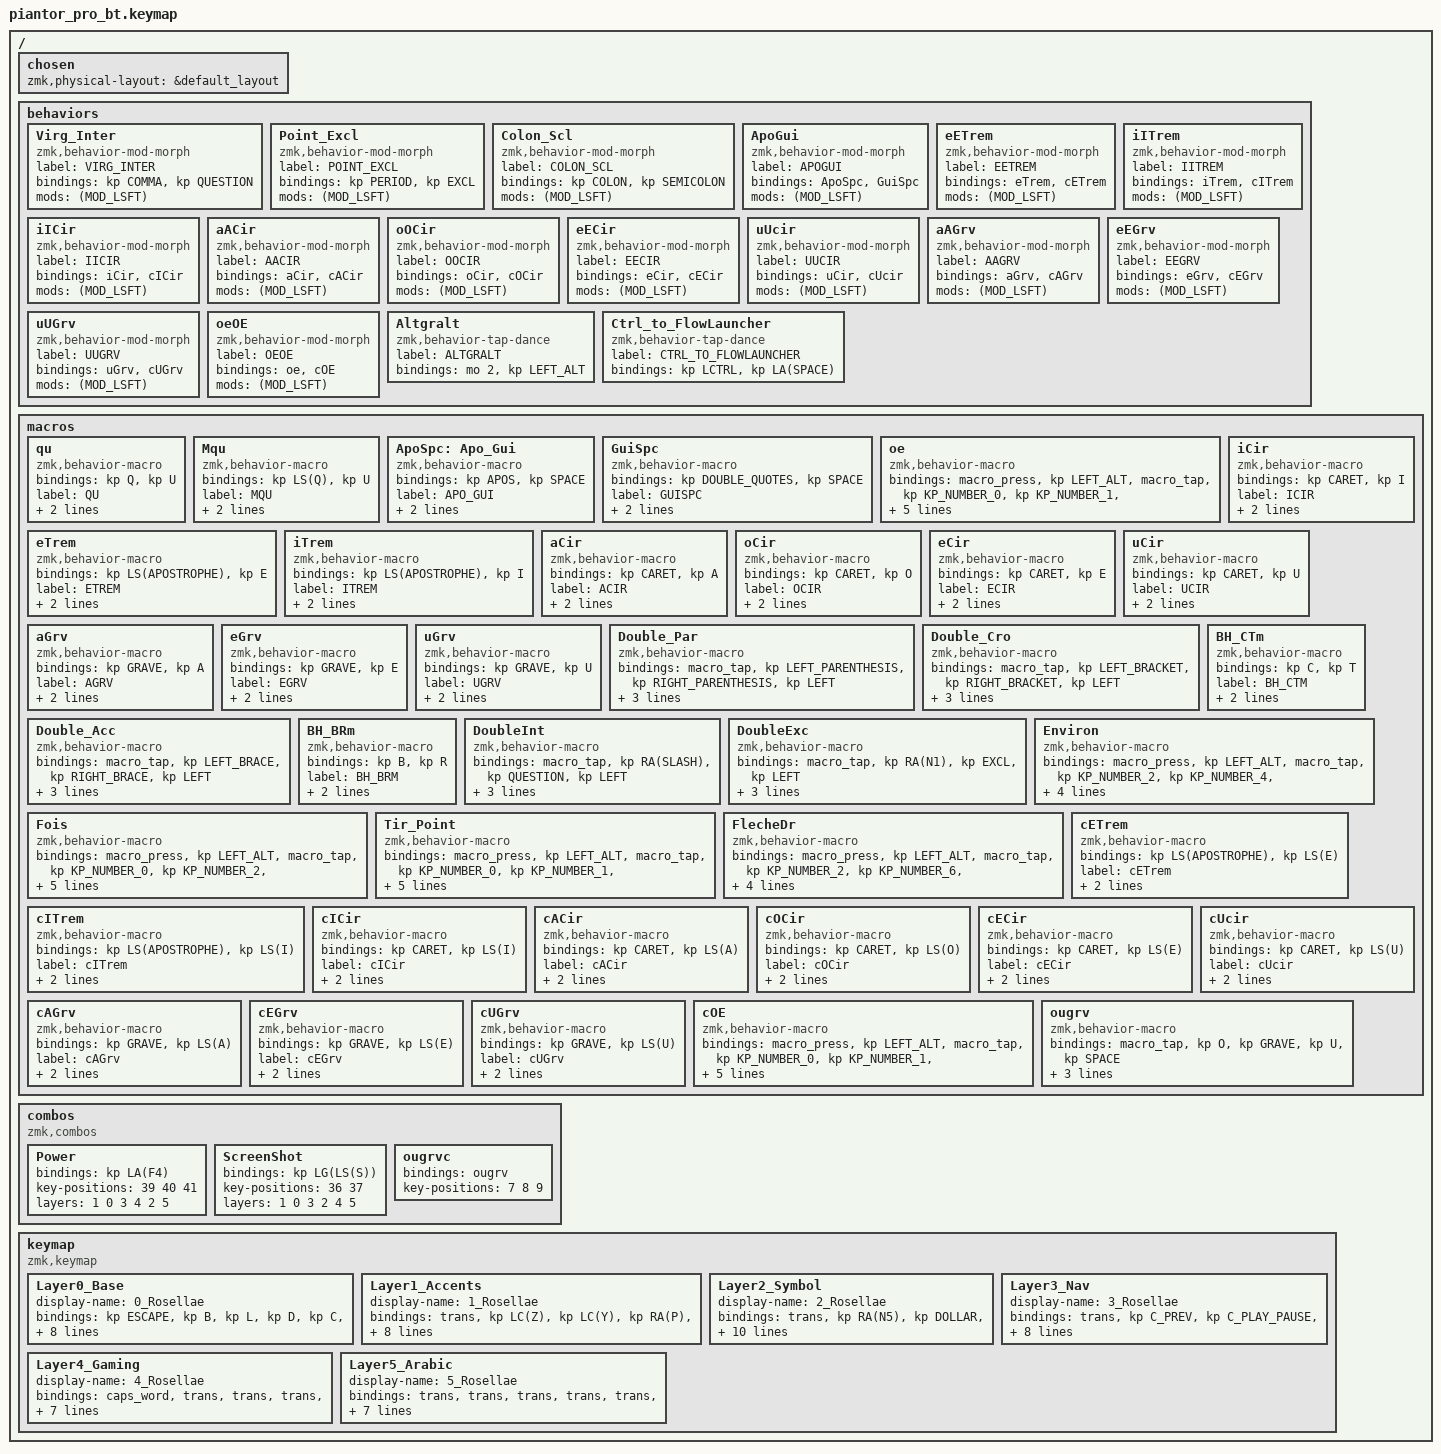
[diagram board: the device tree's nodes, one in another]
/*
 * Copyright (c) 2020 The ZMK Contributors
 *
 * SPDX-License-Identifier: MIT
 */

#include <behaviors.dtsi>
#include <dt-bindings/zmk/keys.h>

/ {
    chosen { zmk,physical-layout = &default_layout; };
};

/ {
    behaviors {
        Virg_Inter: Virg_Inter {
            compatible = "zmk,behavior-mod-morph";
            label = "VIRG_INTER";
            bindings = <&kp COMMA>, <&kp QUESTION>;

            #binding-cells = <0>;
            mods = <(MOD_LSFT)>;
        };

        Point_Excl: Point_Excl {
            compatible = "zmk,behavior-mod-morph";
            label = "POINT_EXCL";
            bindings = <&kp PERIOD>, <&kp EXCL>;

            #binding-cells = <0>;
            mods = <(MOD_LSFT)>;
        };

        Colon_Scl: Colon_Scl {
            compatible = "zmk,behavior-mod-morph";
            label = "COLON_SCL";
            bindings = <&kp COLON>, <&kp SEMICOLON>;

            #binding-cells = <0>;
            mods = <(MOD_LSFT)>;
        };

        ApoGui: ApoGui {
            compatible = "zmk,behavior-mod-morph";
            label = "APOGUI";
            bindings = <&ApoSpc>, <&GuiSpc>;

            #binding-cells = <0>;
            mods = <(MOD_LSFT)>;
        };

        eETrem: eETrem {
            compatible = "zmk,behavior-mod-morph";
            label = "EETREM";
            bindings = <&eTrem>, <&cETrem>;

            #binding-cells = <0>;
            mods = <(MOD_LSFT)>;
        };

        iITrem: iITrem {
            compatible = "zmk,behavior-mod-morph";
            label = "IITREM";
            bindings = <&iTrem>, <&cITrem>;

            #binding-cells = <0>;
            mods = <(MOD_LSFT)>;
        };

        iICir: iICir {
            compatible = "zmk,behavior-mod-morph";
            label = "IICIR";
            bindings = <&iCir>, <&cICir>;

            #binding-cells = <0>;
            mods = <(MOD_LSFT)>;
        };

        aACir: aACir {
            compatible = "zmk,behavior-mod-morph";
            label = "AACIR";
            bindings = <&aCir>, <&cACir>;

            #binding-cells = <0>;
            mods = <(MOD_LSFT)>;
        };

        oOCir: oOCir {
            compatible = "zmk,behavior-mod-morph";
            label = "OOCIR";
            bindings = <&oCir>, <&cOCir>;

            #binding-cells = <0>;
            mods = <(MOD_LSFT)>;
        };

        eECir: eECir {
            compatible = "zmk,behavior-mod-morph";
            label = "EECIR";
            bindings = <&eCir>, <&cECir>;

            #binding-cells = <0>;
            mods = <(MOD_LSFT)>;
        };

        uUcir: uUcir {
            compatible = "zmk,behavior-mod-morph";
            label = "UUCIR";
            bindings = <&uCir>, <&cUcir>;

            #binding-cells = <0>;
            mods = <(MOD_LSFT)>;
        };

        aAGrv: aAGrv {
            compatible = "zmk,behavior-mod-morph";
            label = "AAGRV";
            bindings = <&aGrv>, <&cAGrv>;

            #binding-cells = <0>;
            mods = <(MOD_LSFT)>;
        };

        eEGrv: eEGrv {
            compatible = "zmk,behavior-mod-morph";
            label = "EEGRV";
            bindings = <&eGrv>, <&cEGrv>;

            #binding-cells = <0>;
            mods = <(MOD_LSFT)>;
        };

        uUGrv: uUGrv {
            compatible = "zmk,behavior-mod-morph";
            label = "UUGRV";
            bindings = <&uGrv>, <&cUGrv>;

            #binding-cells = <0>;
            mods = <(MOD_LSFT)>;
        };

        oeOE: oeOE {
            compatible = "zmk,behavior-mod-morph";
            label = "OEOE";
            bindings = <&oe>, <&cOE>;

            #binding-cells = <0>;
            mods = <(MOD_LSFT)>;
        };

        Altgralt: Altgralt {
            compatible = "zmk,behavior-tap-dance";
            label = "ALTGRALT";
            #binding-cells = <0>;
            bindings = <&mo 2>, <&kp LEFT_ALT>;
        };

        Ctrl_to_FlowLauncher: Ctrl_to_FlowLauncher {
            compatible = "zmk,behavior-tap-dance";
            label = "CTRL_TO_FLOWLAUNCHER";
            #binding-cells = <0>;
            bindings = <&kp LCTRL>, <&kp LA(SPACE)>;
        };
    };

    macros {
        qu: qu {
            compatible = "zmk,behavior-macro";
            #binding-cells = <0>;
            bindings = <&kp Q &kp U>;
            label = "QU";
            wait-ms = <0>;
            tap-ms = <5>;
        };

        Mqu: Mqu {
            compatible = "zmk,behavior-macro";
            #binding-cells = <0>;
            bindings = <&kp LS(Q) &kp U>;
            label = "MQU";
            wait-ms = <0>;
            tap-ms = <5>;
        };

        ApoSpc: Apo_Gui {
            compatible = "zmk,behavior-macro";
            #binding-cells = <0>;
            bindings = <&kp APOS &kp SPACE>;
            label = "APO_GUI";
            wait-ms = <0>;
            tap-ms = <5>;
        };

        GuiSpc: GuiSpc {
            compatible = "zmk,behavior-macro";
            #binding-cells = <0>;
            bindings = <&kp DOUBLE_QUOTES &kp SPACE>;
            label = "GUISPC";
            wait-ms = <0>;
            tap-ms = <5>;
        };

        oe: oe {
            compatible = "zmk,behavior-macro";
            #binding-cells = <0>;
            bindings =
                <&macro_press>,
                <&kp LEFT_ALT>,
                <&macro_tap>,
                <&kp KP_NUMBER_0 &kp KP_NUMBER_1 &kp KP_NUMBER_5 &kp KP_NUMBER_6>,
                <&macro_release>,
                <&kp LEFT_ALT>;

            label = "OE";
            wait-ms = <10>;
            tap-ms = <10>;
        };

        eTrem: eTrem {
            compatible = "zmk,behavior-macro";
            #binding-cells = <0>;
            bindings = <&kp LS(APOSTROPHE) &kp E>;
            label = "ETREM";
            wait-ms = <0>;
            tap-ms = <5>;
        };

        iTrem: iTrem {
            compatible = "zmk,behavior-macro";
            #binding-cells = <0>;
            bindings = <&kp LS(APOSTROPHE) &kp I>;
            label = "ITREM";
            wait-ms = <0>;
            tap-ms = <5>;
        };

        iCir: iCir {
            compatible = "zmk,behavior-macro";
            #binding-cells = <0>;
            bindings = <&kp CARET &kp I>;
            label = "ICIR";
            wait-ms = <0>;
            tap-ms = <5>;
        };

        aCir: aCir {
            compatible = "zmk,behavior-macro";
            #binding-cells = <0>;
            bindings = <&kp CARET &kp A>;
            label = "ACIR";
            wait-ms = <0>;
            tap-ms = <5>;
        };

        oCir: oCir {
            compatible = "zmk,behavior-macro";
            #binding-cells = <0>;
            bindings = <&kp CARET &kp O>;
            label = "OCIR";
            wait-ms = <0>;
            tap-ms = <5>;
        };

        eCir: eCir {
            compatible = "zmk,behavior-macro";
            #binding-cells = <0>;
            bindings = <&kp CARET &kp E>;
            label = "ECIR";
            wait-ms = <0>;
            tap-ms = <5>;
        };

        uCir: uCir {
            compatible = "zmk,behavior-macro";
            #binding-cells = <0>;
            bindings = <&kp CARET &kp U>;
            label = "UCIR";
            wait-ms = <0>;
            tap-ms = <5>;
        };

        aGrv: aGrv {
            compatible = "zmk,behavior-macro";
            #binding-cells = <0>;
            bindings = <&kp GRAVE &kp A>;
            label = "AGRV";
            wait-ms = <0>;
            tap-ms = <5>;
        };

        eGrv: eGrv {
            compatible = "zmk,behavior-macro";
            #binding-cells = <0>;
            bindings = <&kp GRAVE &kp E>;
            label = "EGRV";
            wait-ms = <0>;
            tap-ms = <5>;
        };

        uGrv: uGrv {
            compatible = "zmk,behavior-macro";
            #binding-cells = <0>;
            bindings = <&kp GRAVE &kp U>;
            label = "UGRV";
            wait-ms = <0>;
            tap-ms = <5>;
        };

        Double_Par: Double_Par {
            compatible = "zmk,behavior-macro";
            #binding-cells = <0>;
            bindings =
                <&macro_tap>,
                <&kp LEFT_PARENTHESIS &kp RIGHT_PARENTHESIS &kp LEFT>;

            label = "Double_Par";
            wait-ms = <0>;
            tap-ms = <5>;
        };

        Double_Cro: Double_Cro {
            compatible = "zmk,behavior-macro";
            #binding-cells = <0>;
            bindings =
                <&macro_tap>,
                <&kp LEFT_BRACKET &kp RIGHT_BRACKET &kp LEFT>;

            label = "Double_Cro";
            wait-ms = <0>;
            tap-ms = <5>;
        };

        Double_Acc: Double_Acc {
            compatible = "zmk,behavior-macro";
            #binding-cells = <0>;
            bindings = <&macro_tap>, <&kp LEFT_BRACE &kp RIGHT_BRACE &kp LEFT>;

            label = "Double_Acc";
            wait-ms = <0>;
            tap-ms = <5>;
        };

        BH_CTm: BH_CTm {
            compatible = "zmk,behavior-macro";
            #binding-cells = <0>;
            bindings = <&kp C &kp T>;
            label = "BH_CTM";
            wait-ms = <0>;
            tap-ms = <5>;
        };

        BH_BRm: BH_BRm {
            compatible = "zmk,behavior-macro";
            #binding-cells = <0>;
            bindings = <&kp B &kp R>;
            label = "BH_BRM";
            wait-ms = <0>;
            tap-ms = <5>;
        };

        DoubleInt: DoubleInt {
            compatible = "zmk,behavior-macro";
            #binding-cells = <0>;
            bindings = <&macro_tap>, <&kp RA(SLASH) &kp QUESTION &kp LEFT>;

            label = "DOUBLEINT";
            wait-ms = <0>;
            tap-ms = <5>;
        };

        DoubleExc: DoubleExc {
            compatible = "zmk,behavior-macro";
            #binding-cells = <0>;
            bindings = <&macro_tap>, <&kp RA(N1) &kp EXCL &kp LEFT>;

            label = "DOUBLEEXC";
            wait-ms = <0>;
            tap-ms = <5>;
        };

        Environ: Environ {
            compatible = "zmk,behavior-macro";
            #binding-cells = <0>;
            bindings =
                <&macro_press>,
                <&kp LEFT_ALT>,
                <&macro_tap>,
                <&kp KP_NUMBER_2 &kp KP_NUMBER_4 &kp KP_NUMBER_7>,
                <&macro_release>,
                <&kp LEFT_ALT>;

            label = "ENVIRON";
            tap-ms = <10>;
            wait-ms = <10>;
        };

        Fois: Fois {
            compatible = "zmk,behavior-macro";
            #binding-cells = <0>;
            bindings =
                <&macro_press>,
                <&kp LEFT_ALT>,
                <&macro_tap>,
                <&kp KP_NUMBER_0 &kp KP_NUMBER_2 &kp KP_NUMBER_1 &kp KP_NUMBER_5>,
                <&macro_release>,
                <&kp LEFT_ALT>;

            label = "FOIS";
            wait-ms = <10>;
            tap-ms = <10>;
        };

        Tir_Point: Tir_Point {
            compatible = "zmk,behavior-macro";
            #binding-cells = <0>;
            bindings =
                <&macro_press>,
                <&kp LEFT_ALT>,
                <&macro_tap>,
                <&kp KP_NUMBER_0 &kp KP_NUMBER_1 &kp KP_NUMBER_4 &kp KP_NUMBER_9>,
                <&macro_release>,
                <&kp LEFT_ALT>;

            label = "TIR_POINT";
            wait-ms = <10>;
            tap-ms = <10>;
        };

        FlecheDr: FlecheDr {
            compatible = "zmk,behavior-macro";
            #binding-cells = <0>;
            bindings =
                <&macro_press>,
                <&kp LEFT_ALT>,
                <&macro_tap>,
                <&kp KP_NUMBER_2 &kp KP_NUMBER_6>,
                <&macro_release>,
                <&kp LEFT_ALT>;

            label = "FLECHEDR";
            wait-ms = <10>;
            tap-ms = <10>;
        };

        cETrem: cETrem {
            compatible = "zmk,behavior-macro";
            #binding-cells = <0>;
            bindings = <&kp LS(APOSTROPHE) &kp LS(E)>;
            label = "cETrem";
            wait-ms = <0>;
            tap-ms = <5>;
        };

        cITrem: cITrem {
            compatible = "zmk,behavior-macro";
            #binding-cells = <0>;
            bindings = <&kp LS(APOSTROPHE) &kp LS(I)>;
            label = "cITrem";
            wait-ms = <0>;
            tap-ms = <5>;
        };

        cICir: cICir {
            compatible = "zmk,behavior-macro";
            #binding-cells = <0>;
            bindings = <&kp CARET &kp LS(I)>;
            label = "cICir";
            wait-ms = <0>;
            tap-ms = <5>;
        };

        cACir: cACir {
            compatible = "zmk,behavior-macro";
            #binding-cells = <0>;
            bindings = <&kp CARET &kp LS(A)>;
            label = "cACir";
            wait-ms = <0>;
            tap-ms = <5>;
        };

        cOCir: cOCir {
            compatible = "zmk,behavior-macro";
            #binding-cells = <0>;
            bindings = <&kp CARET &kp LS(O)>;
            label = "cOCir";
            wait-ms = <0>;
            tap-ms = <5>;
        };

        cECir: cECir {
            compatible = "zmk,behavior-macro";
            #binding-cells = <0>;
            bindings = <&kp CARET &kp LS(E)>;
            label = "cECir";
            wait-ms = <0>;
            tap-ms = <5>;
        };

        cUcir: cUcir {
            compatible = "zmk,behavior-macro";
            #binding-cells = <0>;
            bindings = <&kp CARET &kp LS(U)>;
            label = "cUcir";
            wait-ms = <0>;
            tap-ms = <5>;
        };

        cAGrv: cAGrv {
            compatible = "zmk,behavior-macro";
            #binding-cells = <0>;
            bindings = <&kp GRAVE &kp LS(A)>;
            label = "cAGrv";
            wait-ms = <0>;
            tap-ms = <5>;
        };

        cEGrv: cEGrv {
            compatible = "zmk,behavior-macro";
            #binding-cells = <0>;
            bindings = <&kp GRAVE &kp LS(E)>;
            label = "cEGrv";
            wait-ms = <0>;
            tap-ms = <5>;
        };

        cUGrv: cUGrv {
            compatible = "zmk,behavior-macro";
            #binding-cells = <0>;
            bindings = <&kp GRAVE &kp LS(U)>;
            label = "cUGrv";
            wait-ms = <0>;
            tap-ms = <5>;
        };

        cOE: cOE {
            compatible = "zmk,behavior-macro";
            #binding-cells = <0>;
            bindings =
                <&macro_press>,
                <&kp LEFT_ALT>,
                <&macro_tap>,
                <&kp KP_NUMBER_0 &kp KP_NUMBER_1 &kp KP_NUMBER_4 &kp KP_NUMBER_0>,
                <&macro_release>,
                <&kp LEFT_ALT>;

            label = "cOE";
            wait-ms = <10>;
            tap-ms = <10>;
        };

        ougrv: ougrv {
            compatible = "zmk,behavior-macro";
            #binding-cells = <0>;
            bindings = <&macro_tap>, <&kp O &kp GRAVE &kp U &kp SPACE>;

            label = "OUGRV";
            wait-ms = <0>;
            tap-ms = <5>;
        };
    };

    combos {
        compatible = "zmk,combos";

        Power {
            bindings = <&kp LA(F4)>;
            key-positions = <39 40 41>;
            layers = <1 0 3 4 2 5>;
        };

        ScreenShot {
            bindings = <&kp LG(LS(S))>;
            key-positions = <36 37>;
            layers = <1 0 3 2 4 5>;
        };

        ougrvc {
            bindings = <&ougrv>;
            key-positions = <7 8 9>;
        };
    };

    keymap {
        compatible = "zmk,keymap";

        Layer0_Base {
            display-name = "0_Rosellae";

            // --------------------------------------------------------------------------------
            // |  TAB |  Q  |  W  |  E  |  R  |  T  |  Y  |  U   |  I  |  O  |  P  | BSPC |
            // | CTRL |  A  |  S  |  D  |  F  |  G  |  H  |  J   |  K  |  L  |  ;  |  '   |
            // | SHFT |  Z  |  X  |  C  |  V  |  B  |  N  |  M   |  ,  |  .  |  /  | ESC  |
            //                    | GUI | LWR | SPC | ENT | RSE  | ALT |

            bindings = <
&kp ESCAPE  &kp B  &kp L  &kp D  &kp C  &kp V  &kp Z  &ApoGui  &kp O  &kp U  &kp X  &kp BSPC  &kp TAB  &kp N  &kp R  &kp T  &kp S  &kp F  &kp Y  &kp H  &kp E  &kp I  &kp A  &kp ENTER  &kp LEFT_WIN  &qu  &kp J  &kp M  &kp G  &kp W  &kp K  &kp P  &Virg_Inter  &Point_Excl  &Colon_Scl  &kp LC(LSHIFT)  &sk LEFT_SHIFT  &sl 1  &Ctrl_to_FlowLauncher  &mo 3  &kp SPACE  &Altgralt
            >;
        };

        Layer1_Accents {
            display-name = "1_Rosellae";

            // -----------------------------------------------------------------------------------------
            // |  TAB |  1  |  2  |  3  |  4  |  5    |  6  |  7  |  8  |  9  |  0  | BSPC |
            // | CTRL | BT1 | BT2 | BT3 | BT4 | BT5   | LFT | DWN |  UP | RGT |     |      |
            // | SHFT | BTCR| RGB | RST | BOOT| Unlock|     |     |     |     |     |      |
            //                    | GUI |     | SPC   | ENT |     | ALT |

            bindings = <
&trans  &kp LC(Z)  &kp LC(Y)  &kp RA(P)  &kp RA(Y)  &none  &uUGrv  &iICir  &eECir  &uUcir  &kp RA(O)  &kp DELETE  &kp LA(TAB)  &kp RA(Z)  &kp RA(N)  &oeOE  &eETrem  &kp RA(Q)  &kp RA(U)  &kp RA(COMMA)  &aAGrv  &eEGrv  &kp RA(E)  &trans  &kp LS(LC(TAB))  &kp Q  &kp LC(X)  &kp LC(C)  &kp LC(V)  &kp LC(A)  &iITrem  &aACir  &oOCir  &kp RA(I)  &kp RA(A)  &trans  &trans  &trans  &trans  &trans  &trans  &trans
            >;
        };

        Layer2_Symbol {
            display-name = "2_Rosellae";

            // -----------------------------------------------------------------------------------------
            // |  TAB |  !  |  @  |  #  |  $  |  %  |  ^  |  &  |  *  |  (  |  )  | BSPC |
            // | CTRL | HUD | HUI |     |     |     |  -  |  =  |  [  |  ]  |  \  |  `   |
            // | SHFT |     |     |     |     |     |  _  |  +  |  {  |  }  | "|" |  ~   |
            //                    | GUI |     | SPC | ENT |     | ALT |

            bindings = <
&trans  &kp RA(N5)  &kp DOLLAR  &Double_Cro  &kp CARET  &kp TILDE  &none  &kp LESS_THAN  &kp GREATER_THAN  &kp AMPERSAND  &kp NON_US_BACKSLASH  &trans  &trans  &kp PLUS  &kp EQUAL  &Double_Par  &kp ASTERISK  &FlecheDr  &kp HASH  &kp UNDERSCORE  &kp MINUS  &kp AT_SIGN  &kp SLASH  &trans  &trans  &Mqu  &Fois  &Double_Acc  &kp GRAVE  &none  &none  &kp PERCENT  &DoubleInt  &DoubleExc  &kp PIPE  &trans  &trans  &trans  &trans  &trans  &trans  &trans
            >;
        };

        Layer3_Nav {
            display-name = "3_Rosellae";
            bindings = <
&trans  &kp C_PREV  &kp C_PLAY_PAUSE  &kp C_NEXT  &kp END  &kp PAGE_DOWN  &kp PG_UP  &kp HOME  &kp F2  &kp F4  &kp F11  &trans  &trans  &kp LEFT_ARROW  &kp DOWN_ARROW  &kp UP_ARROW  &kp RIGHT  &kp MINUS  &kp SLASH  &kp COMMA  &kp N4  &kp N5  &kp N6  &trans  &trans  &kp N1  &kp N2  &kp N3  &kp N0  &kp PLUS  &kp EQUAL  &kp N7  &kp N8  &kp N9  &kp PERIOD  &trans  &trans  &trans  &trans  &trans  &trans  &trans
            >;
        };

        Layer4_Gaming {
            display-name = "4_Rosellae";
            bindings = <
&caps_word  &trans  &trans  &trans  &trans  &trans  &trans  &trans  &trans  &trans  &trans  &trans  &trans  &trans  &trans  &trans  &trans  &trans  &trans  &trans  &trans  &trans  &trans  &trans  &trans  &trans  &trans  &trans  &trans  &trans  &trans  &trans  &trans  &trans  &trans  &trans  &kp R  &kp UP_ARROW  &kp SPACE  &kp SPACE  &kp UP_ARROW  &kp R
            >;
        };

        Layer5_Arabic {
            display-name = "5_Rosellae";
            bindings = <
&trans  &trans  &trans  &trans  &trans  &trans  &trans  &trans  &trans  &trans  &trans  &trans  &trans  &trans  &trans  &trans  &trans  &trans  &trans  &trans  &trans  &trans  &trans  &trans  &trans  &trans  &trans  &trans  &trans  &trans  &trans  &trans  &trans  &trans  &trans  &trans  &trans  &trans  &trans  &trans  &trans  &trans
            >;
        };
    };
};
